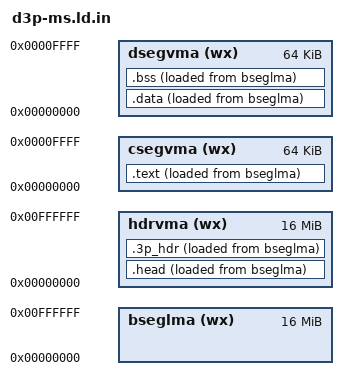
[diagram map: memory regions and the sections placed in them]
#!/bin/sh

set -e
cmd1='#'
cmd2='#'
w1=with
w2=with
crt0='-l:dpm-@cmodel@-c0.o'
cm=s
cml=small
while [ $# -gt 0 ]; do
  case "$1" in
    -nostdlib)
      cmd1='/^@if_starts@/,/^@endif@/ d'
      cmd2='/^@if_libs@/,/^@endif@/ d'
      w1=without
      w2=without;;
    -nostartfiles)
       cmd1='/^@if_starts@/,/^@endif@/ d'
       w1=without;;
    -nodefaultlibs)
       cmd2='/^@if_libs@/,/^@endif@/ d'
       w2=without;;
    -mcmodel=medium)
       cm=m
       cml=medium;;
  esac
  shift
done
sed -e "$cmd1" -e "$cmd2" -e "s;@crt0@;$crt0;g" \
    -e "s;@withstarts@;$w1;g" -e "s;@withlibs@;$w2;g" \
    -e "s;@withdpmiable@;$w3;g" \
    -e "s;@cmodel@;$cm;g" -e "s;@cmodel_long@;$cml;g" \
    -e "s/@self@/`basename "$0"`/g" -e "/^@if/ d" -e "/^@endif@/ d" <<'EPART1'
/*
 * Linker script for @cmodel_long@-model CauseWay DOS extender 3P 16-bit
 * executables, @withstarts2 startup files, and @withlibs@ default libraries.
 *
 * WARNING: the internals of this linker script are extremely experimental,
 * and subject to change.
 *
 * Partly derived from elks-separate.ld .  Generated from @self@.
 */

OUTPUT_FORMAT(binary)
ENTRY(_start)
@if_starts@
INPUT(-l:crtbegin.o -l:crtend.o @crt0@)
@endif@
@if_libs@
GROUP(-lc -lgcc -ldos-@cmodel@ -lm)
@endif@

MEMORY
  {
    bseglma	(wx) : ORIGIN = 0x00000, LENGTH = 0x1000000
    hdrvma	(wx) : ORIGIN = 0x00000, LENGTH = 0x1000000
    csegvma	(wx) : ORIGIN = 0x00000, LENGTH = 0x10000
    dsegvma	(wx) : ORIGIN = 0x00000, LENGTH = 0x10000
  }

SECTIONS
  {
    .head : {
		*(.head) *(.head.*)
	} >hdrvma AT>bseglma

    /* Fabricate a CauseWay 3P header here. */
    .3p_hdr : {
		HIDDEN (__3p_hdr_start = .);

		/* Signature. */
		SHORT (0x5033)
		/* Size of this 3P module. */
		LONG (LOADADDR (.data) + SIZEOF (.data) - LOADADDR (.3p_hdr))
		/* Size of program image. */
		LONG (LOADADDR (.data) + SIZEOF (.data) - LOADADDR (.text))
		/* Program memory required. */
		LONG (LOADADDR (.data) + 0x10000 - LOADADDR (.text))
		/* Number of segment definitions. */
		SHORT (2)
		/* Number of relocation table entries. */
		LONG (0)
		/* Initial %cs:%eip. */
		LONG (_start)
		SHORT (0)
		/* Initial %ss:%esp. */
		LONG (0xfffe)
		SHORT (1)
		/*
		 * Executable flags:
		 *   * bit 0: 16-bit interrupt stack frame
		 *   * bit 7: use LDT, not GDT
		 *   * bit 14: 16-bit default data size
		 */
		LONG (1 << 0 | 1 << 7 | 1 << 14)
		/* Automatic stack size if initial %esp == 0. */
		LONG (0)
		/* Number of automatic data segments + 1, or 0 if none. */
		SHORT (0)
		/* Length of EXPORT section. */
		LONG (0)
		/* Length of IMPORT section. */
		LONG (0)
		/* Number of IMPORT modules. */
		LONG (0)
		/* Reserved. */
		. = . + 10;

		/* Segment definition for initial %cs. */
		LONG (LOADADDR (.text) - __3p_hdr_len);
		LONG (__etext | 0 << 21 | 1 << 25)

		/* Segment definition for initial %ds == %ss. */
		LONG (LOADADDR (.data) - __3p_hdr_len);
		LONG (0x10000 | 1 << 21 | 1 << 25)

		HIDDEN (__3p_hdr_len = . - __3p_hdr_start);
	} >hdrvma AT>bseglma

    /* Target text sections.  */
    .text : {
		__stext = .;
		*(.startupA)
		*(.startupB)
		*(.startupC)
		*(.msdos_init) *(.msdos_init.*)
		*(.startupD)
		*(.init)
		*(.startupE)
		*(.exitA)
		*(.fini)
		*(.exitB)
		*(.text) *(.text.*)
		__etext = .;

		/* Make the data segments start on a paragraph boundary.  */
		. = ALIGN (16);
		__etext_padded = .;

		ASSERT(. <= 0x10000,
		    "Error: too large for a small-model .exe file.");

	} >csegvma AT >bseglma
	__ltext = __etext - __stext;
	__ltext_padded = __etext_padded - __stext;

    /* Target data section.  */
    .data : {
		__sdata = .;

		/* Build lists of constructors and destructors.  */
		KEEP (*crtbegin*.o(.ctors))
		KEEP (*(EXCLUDE_FILE (*crtend*.o ) .ctors))
		KEEP (*(SORT(.ctors.*)))
		KEEP (*(.ctors))

		KEEP (*crtbegin*.o(.dtors))
		KEEP (*(EXCLUDE_FILE (*crtend*.o ) .dtors))
		KEEP (*(SORT(.dtors.*)))
		KEEP (*(.dtors))

		*(.msdos_init_rodata) *(.msdos_init_rodata.*)
		*(.rodata) *(.rodata.*)
		*(.data) *(.data.*)
		*(.gcc_except_table)
		__edata = .;

		/* GNU ld said
			"section .text VMA [0000000000000020,000000000000002f]
			overlaps section .msdos_mz_hdr VMA [0000000000000000,
			00000000000001ff]"
		   for gcc-ia16's ia16/torture/nostdlib-1.c test, because ld's
		   overlay checks saw only two non-empty overlapping segments,
		   .text and .msdos_mz_hdr, and they did not start at the
		   same address.

		   To work around this, put something inside .data if it might
		   be necessary.  -- tkchia  */
		. = (. == __sdata ? . + 1 : .);

		/* ".../ia16-elf/bin/ld: a.out: R_386_RELSEG16 with
		   unaligned section `.bss'" */
		. = ALIGN (16);
		__edata_padded = .;
	} >dsegvma AT >bseglma

    .bss (NOLOAD) : {
		 __sbss = .;
                *(.bss) *(.bss.*)
                *(COMMON)
                __ebss = .;

                /* Minimum address allowed for sbrk() to use.  */
                __heap_end_minimum = ALIGN(8);

		ASSERT(. <= 0xfd00,
		    "Error: too large for a small-model .exe file.");
		ASSERT (ABSOLUTE (DEFINED ("main!") ? "main!" : 0) == 0,
		    "Error: using non-segelf ld script with segelf program.");
		ASSERT (ABSOLUTE (DEFINED ("environ!") ? "environ!" : 0) == 0,
		    "Error: using non-segelf ld script with segelf library.");
	} >dsegvma AT >bseglma

	__ldata = __edata - __sdata;
	__lbss = (__ebss - __sbss + 1) / 2;

    /DISCARD/ : { *(.*) }
  }
EPART1
